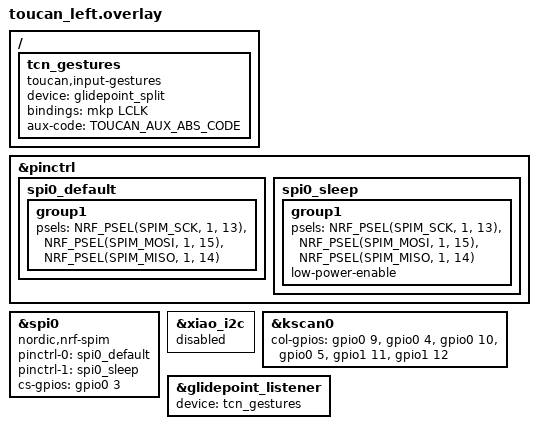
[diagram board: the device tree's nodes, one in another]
#define TOUCAN_POINTER_SMOOTH
#include "toucan.dtsi"
#include <behaviors/toucan_runtime_macro.dtsi>
#include <dt-bindings/zmk/mouse.h>
#include <dt-bindings/toucan/touch_gestures.h>

&pinctrl {
    spi0_default: spi0_default {
        group1 {
            psels = <NRF_PSEL(SPIM_SCK, 1, 13)>,
                <NRF_PSEL(SPIM_MOSI, 1, 15)>,
                <NRF_PSEL(SPIM_MISO, 1, 14)>;
        };
    };

     spi0_sleep: spi0_sleep {
        group1 {
            psels = <NRF_PSEL(SPIM_SCK, 1, 13)>,
                    <NRF_PSEL(SPIM_MOSI, 1, 15)>,
                    <NRF_PSEL(SPIM_MISO, 1, 14)>;
            low-power-enable;
        };
    };

};

nice_view_spi: &spi0 {
   compatible = "nordic,nrf-spim";
   pinctrl-0 = <&spi0_default>;
   pinctrl-1 = <&spi0_sleep>;
   pinctrl-names = "default", "sleep";
   cs-gpios = <&gpio0 3 GPIO_ACTIVE_HIGH>;
};

&xiao_i2c {
    status = "disabled";
};

&kscan0 {
    col-gpios
    = <&gpio0 9 GPIO_ACTIVE_HIGH>
    , <&gpio0 4 GPIO_ACTIVE_HIGH>
    , <&gpio0 10 GPIO_ACTIVE_HIGH>
    , <&gpio0 5 GPIO_ACTIVE_HIGH>
    , <&gpio1 11 GPIO_ACTIVE_HIGH>
    , <&gpio1 12 GPIO_ACTIVE_HIGH>
    ;
};

/ {
    // Tap-to-click between the right half's trackpad and the listener (off by default; Studio
    // turns it on, &tgs turns it off). Forwards everything else unchanged.
    tcn_gestures: tcn_gestures {
        compatible = "toucan,input-gestures";
        device = <&glidepoint_split>;
        bindings = <&mkp LCLK>;
        aux-code = <TOUCAN_AUX_ABS_CODE>;
    };
};

&glidepoint_listener {
    status = "okay";
    device = <&tcn_gestures>;
};
